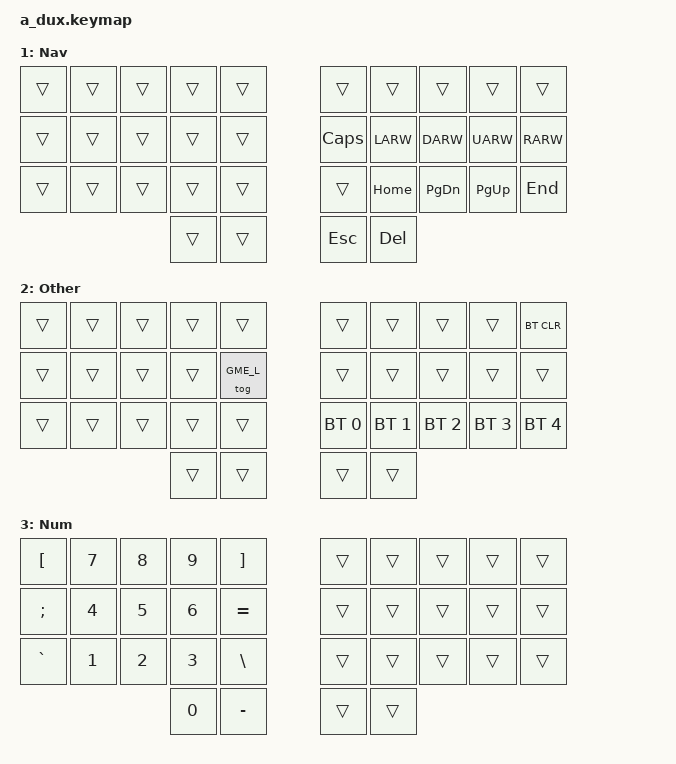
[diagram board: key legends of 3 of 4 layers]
/*
 * Copyright (c) 2021 Pete Johanson, modified by Dionysus
 *
 * SPDX-License-Identifier: MIT
 */

#include <behaviors.dtsi>
#include <dt-bindings/zmk/keys.h>
#include <dt-bindings/zmk/bt.h>
#include <dt-bindings/zmk/outputs.h>

#define BSE_L 0
#define LOWER 1
#define RAISE 2
#define ADJUST 3

// Using layer taps on thumbs, having quick tap as well helps w/ repeating space/backspace
&lt { quick_tap_ms = <200>; };

/ {
    combos {
        compatible = "zmk,combos";

        fn_mo {
	    timeout-ms = <50>;
            key-positions = <32 33>;
            bindings = <&mo FUN_L>;
        };

	/*
        caps_word_combo {
	    timeout-ms = <50>;
            key-positions = <13 16>;
            bindings = <&caps_word>;
        };
	*/
    };

    behaviors {
        hm: homerow_mods {
            compatible = "zmk,behavior-hold-tap";
            label = "homerow mods";
            #binding-cells = <2>;
            tapping_term_ms = <200>;
            flavor = "tap-preferred";
            bindings = <&kp>, <&kp>;
        };
    };

    keymap {
        compatible = "zmk,keymap";

        default_layer {
            label = "Base";
            bindings = <
                &kp K      &kp L      &kp F       &kp P          &kp B         &kp Q            &kp J          &kp O       &kp U      &lt LAYER_4 ;
                &hm LGUI H &hm LALT R &hm LCTRL S &hm LSHFT T    &kp G         &kp X            &hm RSHFT N    &hm RCTRL E &hm LALT I &hm LGUI A
                &kp M      &kp W      &kp C       &kp D          &kp V         &kp Z            &kp Y          &kp APOS   &kp DOT    &kp COMMA
                                                  &lt LAYER_2 BKSP  &kp LSHIFT &kp RGUI  &lt LAYER_3 BKSP
            >;
        };

        layer_2 {
            label = "Nav";
            bindings = <
                &trans     &trans     &trans      &trans          &trans       &trans           &trans         &trans      &trans     &trans
                &trans     &trans     &trans      &trans          &trans       &kp CAPS         &kp LARW       &kp DARW    &kp UARW   &kp RARW
                &trans     &trans     &trans      &trans          &trans       &trans           &kp HOME       &kp PG_DN   &kp PG_UP  &kp END
                                                  &trans          &trans       &kp ESC          &kp DEL
            >;
        };
	
	layer_3 {
            label = "Other";
            bindings = <
                &trans	   &trans     &trans      &trans          &trans       &trans           &trans         &trans       &trans       &bt BT_CLR
                &trans     &trans     &trans      &trans          &tog GME_L   &trans           &trans         &trans       &trans       &trans
                &trans     &trans     &trans      &trans          &trans       &bt BT_SEL 0     &bt BT_SEL 1   &bt BT_SEL 2 &bt BT_SEL 3 &bt BT_SEL 4
                                                  &trans          &trans       &trans           &trans
            >;
        };

        layer_4 {
            label = "Num";
            bindings = <
                &kp LBKT   &kp N7     &kp N8      &kp N9          &kp RBKT      &trans          &trans         &trans      &trans     &trans
                &kp SEMI   &kp N4     &kp N5      &kp N6          &kp EQUAL     &trans          &trans         &trans      &trans     &trans
                &kp GRAVE  &kp N1     &kp N2      &kp N3          &kp BSLH      &trans          &trans         &trans      &trans     &trans
                                                  &kp N0          &kp MINUS     &trans          &trans
            >;
        };

    };
};
